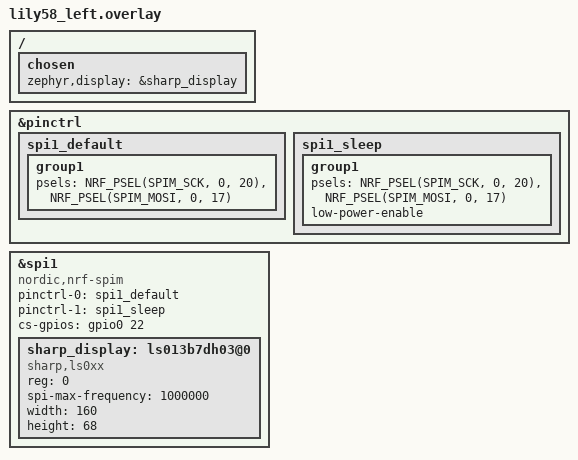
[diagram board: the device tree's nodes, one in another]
/*
 * Lily58 Simple Sharp Display - Using your wiring
 * CS=P0.22(D4), SCK=P0.20(D3), MOSI=P0.17(D2)
 */

/ {
    chosen {
        zephyr,display = &sharp_display;
    };
};

// Configure pinctrl for SPI1 with your exact pins
&pinctrl {
    spi1_default: spi1_default {
        group1 {
            psels = <NRF_PSEL(SPIM_SCK, 0, 20)>,   // P0.20 = D3 = SCK
                    <NRF_PSEL(SPIM_MOSI, 0, 17)>;  // P0.17 = D2 = MOSI
        };
    };

    spi1_sleep: spi1_sleep {
        group1 {
            psels = <NRF_PSEL(SPIM_SCK, 0, 20)>,
                    <NRF_PSEL(SPIM_MOSI, 0, 17)>;
            low-power-enable;
        };
    };
};

// Use SPI1 with your exact pin configuration
&spi1 {
    status = "okay";
    compatible = "nordic,nrf-spim";
    pinctrl-0 = <&spi1_default>;
    pinctrl-1 = <&spi1_sleep>;
    pinctrl-names = "default", "sleep";
    cs-gpios = <&gpio0 22 GPIO_ACTIVE_HIGH>; // P0.22 = D4 = CS
    
    sharp_display: ls013b7dh03@0 {
        compatible = "sharp,ls0xx";
        reg = <0>;
        spi-max-frequency = <1000000>;
        width = <160>;
        height = <68>;
    };
};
